# CH32V203G6U6 register map
Vendor: WCH; File version: 0.1.0
HAIR extraction for the WCH CH32V203G6U6 using the approved WCH datasheet/reference materials, official openwch SDK assets, and exact-family/variant structured cross-checks.
CPU: QingKe V4B V4B, little endian, no MPU, no FPU, vendor SysTick, 4 interrupt priority bits
Registers are 16-bit, read-write, reset 0x0 unless marked. A register's access mark holds for its fields unless they carry their own. Offsets are from the block's base; lines under a group give offsets from that group; [hi:lo] are bit positions; {n}, {i} and the like mark numbered series; 'fields as' and 'values as' point back to an identical list; <NAME> marks a mode.

## Memory map
0x40000000 TIM2 size 0x4E — General-purpose timer 2
0x40000400 TIM3 size 0x4E — General-purpose timer 3
0x40000800 TIM4 size 0x4E — General-purpose timer 4
0x40002800 RTC size 0x26 — Real-time clock
0x40002C00 WWDG size 0xC — Window watchdog
0x40003000 IWDG size 0x10 — Independent watchdog
0x40004400 USART2 size 0x1A — USART controller 2
0x40005400 I2C1 size 0x22 — I2C controller 1
0x40006400 CAN1 size 0x320 — bxCAN controller
0x40006C00 BKP size 0xBE — Backup register block
0x40007000 PWR size 0x8 — Power control block
0x40010000 AFIO size 0x20 — Alternate-function and pin remap controller
0x40010400 EXTI size 0x18 — External interrupt/event controller
0x40010800 GPIOA size 0x1C — GPIO port A
0x40010C00 GPIOB size 0x1C — GPIO port B
0x40011000 GPIOC size 0x1C — GPIO port C
0x40011400 GPIOD size 0x1C — GPIO port D
0x40012400 ADC1 size 0x50 — 12-bit ADC unit 1 / TouchKey block
0x40012800 ADC2 size 0x50 — 12-bit ADC unit 2 / TouchKey block
0x40012C00 TIM1 size 0x4E — Advanced-control timer 1
0x40013000 SPI1 size 0x26 — SPI controller 1
0x40013800 USART1 size 0x1A — USART controller 1
0x40020000 DMA1 size 0xA4 — General-purpose DMA controller
0x40021000 RCC size 0x30 — Reset and clock control block
0x40022000 FLASH size 0x28 — Flash interface controller
0x40023000 CRC size 0xC — CRC calculation unit
0x40023804 OPA size 0x4 — Dual operational-amplifier / comparator block
0x50000000 USBD size 0x5C — USB device-only interface
0xE000E000 PFIC size 0xD14 — Program Fast Interrupt Controller

## Interrupts
16 WWDG — Window Watchdog
17 PVD (PWR) — PVD through EXTI Line detect
18 TAMPER (BKP)
19 RTC (RTC, BKP)
20 FLASH
21 RCC
22 EXTI0 (EXTI) — EXTI Line 0
23 EXTI1 (EXTI) — EXTI Line 1
24 EXTI2 (EXTI) — EXTI Line 2
25 EXTI3 (EXTI) — EXTI Line 3
26 EXTI4 (EXTI) — EXTI Line 4
27 DMA1_Channel1 (DMA1)
28 DMA1_Channel2 (DMA1)
29 DMA1_Channel3 (DMA1)
30 DMA1_Channel4 (DMA1)
31 DMA1_Channel5 (DMA1)
32 DMA1_Channel6 (DMA1)
33 DMA1_Channel7 (DMA1)
34 ADC1_2 (ADC1, ADC2)
35 USB_HP_CAN1_TX (CAN1, USBD) — USB HP and CAN1 TX
36 USB_LP_CAN1_RX0 (CAN1, USBD) — USB LP and CAN1RX0
37 CAN1_RX1 (CAN1)
38 CAN1_SCE (CAN1)
39 EXTI9_5 (EXTI) — EXTI Line 9..5
40 TIM1_BRK (TIM1) — TIM1 Break
41 TIM1_UP (TIM1) — TIM1 Update
42 TIM1_TRG_COM (TIM1) — TIM1 Trigger and Commutation
43 TIM1_CC (TIM1) — TIM1 Capture Compare
44 TIM2
45 TIM3
46 TIM4
47 I2C1_EV (I2C1) — I2C1 Event
48 I2C1_ER (I2C1) — I2C1 Error
51 SPI1
53 USART1
54 USART2
56 EXTI15_10 (EXTI) — EXTI Line 15..10
57 RTCAlarm (RTC, BKP) — RTC Alarm through EXTI Line
58 USBWakeUp (USBD) — USB Wake up from suspend
62 DMA1_Channel8 (DMA1)

## RTC — Real-time clock
Base 0x40002800
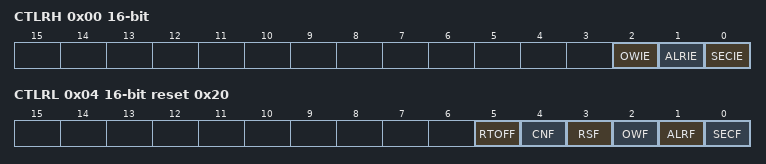
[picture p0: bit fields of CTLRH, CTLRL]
0x00 CTLRH — RTC Control Register High
  [2] OWIE — Overflow interrupt Enable
  [1] ALRIE — Alarm interrupt Enable
  [0] SECIE — Second interrupt Enable
0x04 CTLRL reset 0x20 — RTC Control Register Low
  [5] RTOFF ro — RTC operation OFF
  [4] CNF — Configuration Flag
  [3] RSF — Registers Synchronized Flag
  [2] OWF — Overflow Flag
  [1] ALRF — Alarm Flag
  [0] SECF — Second Flag
0x08 PSCRH — RTC Prescaler Load Register High
0x0C PSCRL reset 0x8000 — RTC Prescaler Load Register Low
0x10 DIVH — RTC Prescaler Divider Register High
  [3:0] RTC_DIV
0x14 DIVL reset 0x8000 — RTC Prescaler Divider Register Low
  [15:0] RTC_DIV
0x18 CNTH — RTC Counter Register High
  [15:0] RTC_CNT
0x1C CNTL — RTC Counter Register Low
  [15:0] RTC_CNT
0x20 ALRMH reset 0xFFFF — RTC Alarm Register High
  [15:0] RTC_ALRM
0x24 ALRML reset 0xFFFF — RTC Alarm Register Low
  [15:0] RTC_ALRM
